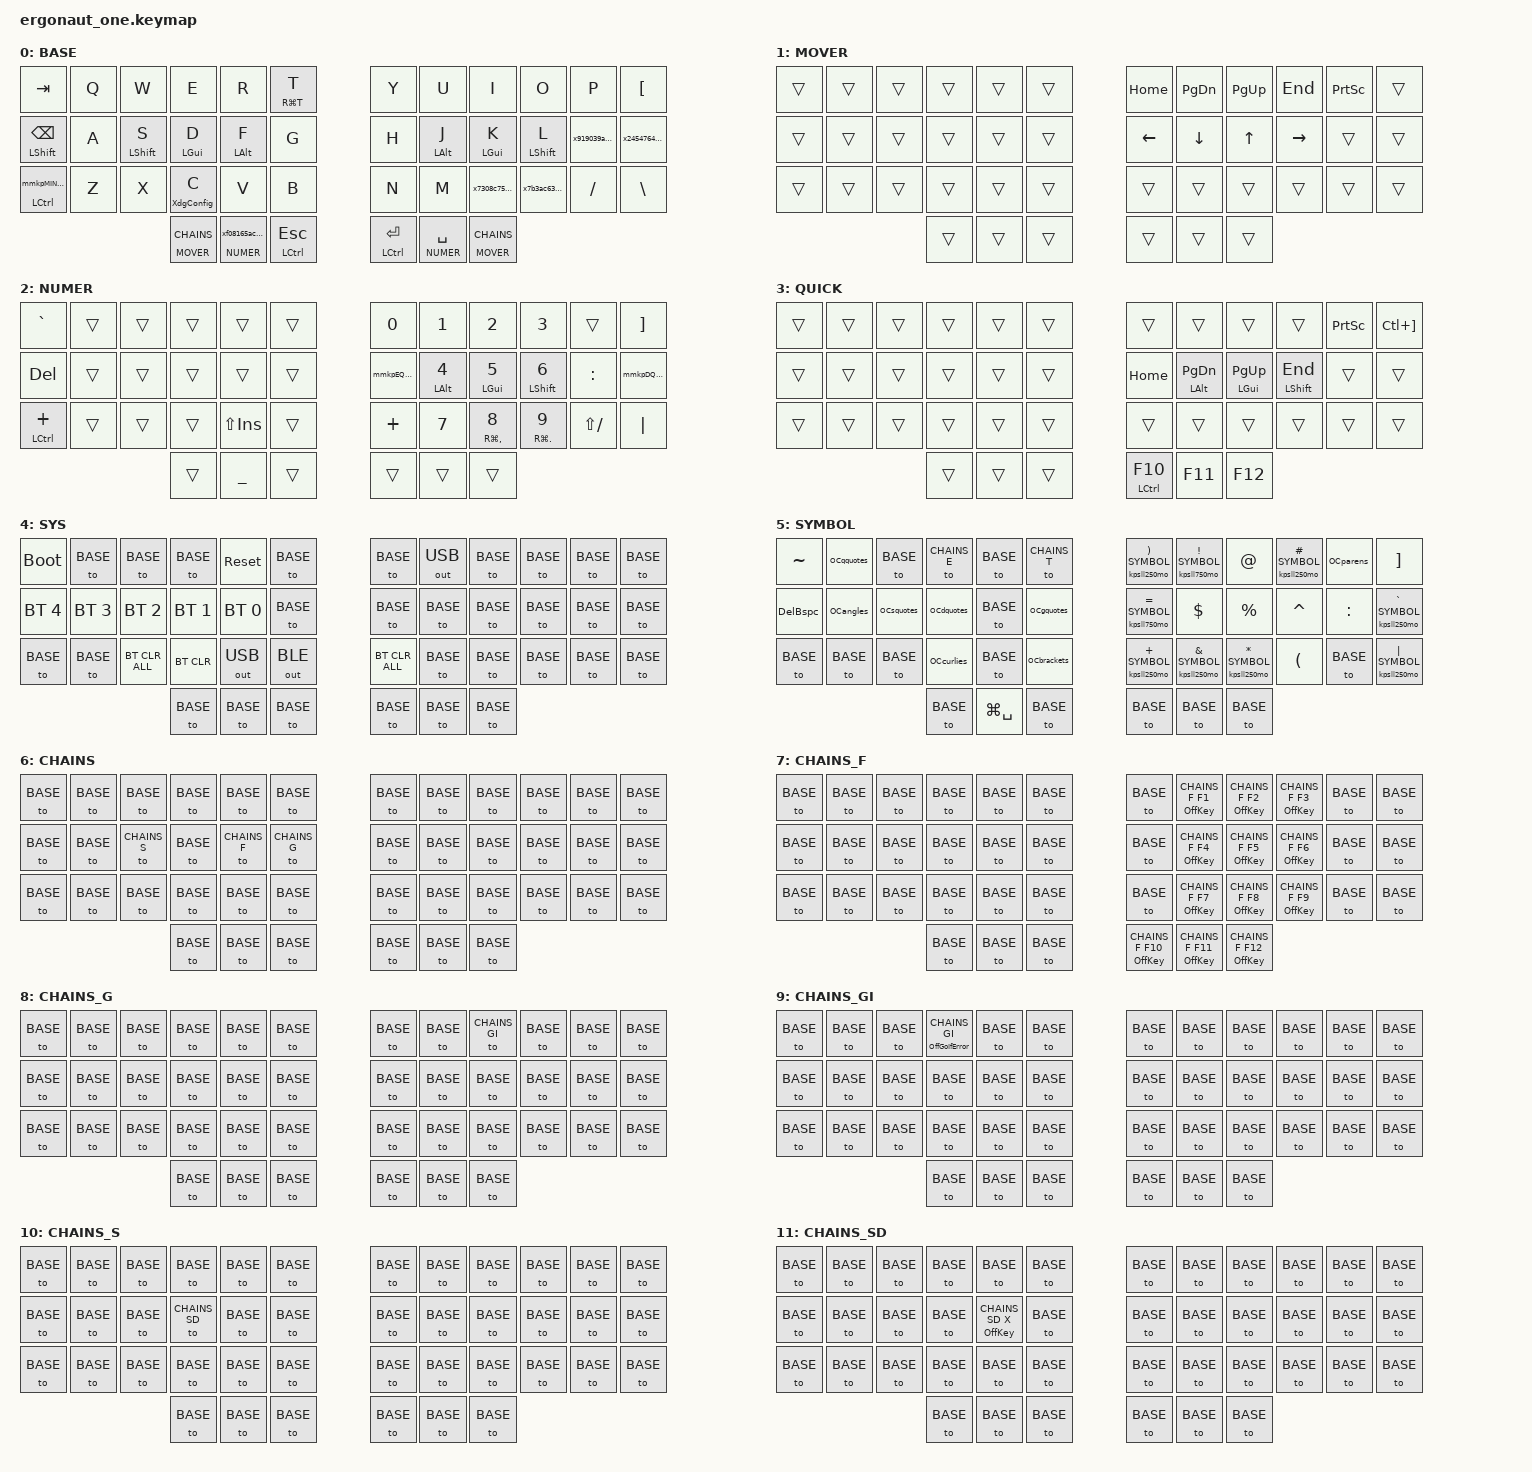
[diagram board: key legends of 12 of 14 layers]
#include <behaviors.dtsi>
#include <dt-bindings/zmk/bt.h>
#include <dt-bindings/zmk/keys.h>
#include <dt-bindings/zmk/outputs.h>
#include <dt-bindings/zmk/pointing.h>

#define BASE 0
#define MOVER 1
#define NUMER 2
#define QUICK 3
#define SYS 4
#define SYMBOL 5
#define CHAINS 6
#define CHAINS_F 7
#define CHAINS_G 8
#define CHAINS_GI 9
#define CHAINS_S 10
#define CHAINS_SD 11
#define CHAINS_E 12
#define CHAINS_T 13

&lt {
    quick-tap-ms = <200>;
    flavor = "balanced";
};

&mt {
    quick-tap-ms = <200>;
    flavor = "tap-preferred";
};

&caps_word {
    continue-list = <UNDER BSPC DEL LEFT RIGHT UP DOWN PG_UP PG_DN>;
};

/ {
    conditional_layers {
        compatible = "zmk,conditional-layers";
    };

    behaviors {
        OlHtOlKpkp: OlHtOlKpkp {
            compatible = "zmk,behavior-hold-tap";
            #binding-cells = <2>;
            bindings = <&OlKp &kp>;
            flavor = "tap-preferred";
            quick-tap-ms = <0>;
            tapping-term-ms = <300>;
        };

        htTapNoRepeatkp: htTapNoRepeatkp {
            compatible = "zmk,behavior-hold-tap";
            #binding-cells = <2>;
            bindings = <&TapNoRepeat &kp>;
            flavor = "tap-preferred";
            quick-tap-ms = <200>;
            tapping-term-ms = <200>;
        };

        htkpcaps_word: htkpcaps_word {
            compatible = "zmk,behavior-hold-tap";
            #binding-cells = <2>;
            bindings = <&kp &caps_word>;
            flavor = "tap-preferred";
            quick-tap-ms = <200>;
            tapping-term-ms = <200>;
        };

        htkpsklkp: htkpsklkp {
            compatible = "zmk,behavior-hold-tap";
            #binding-cells = <2>;
            bindings = <&kp &sklkp>;
            flavor = "tap-preferred";
            quick-tap-ms = <200>;
            tapping-term-ms = <200>;
        };

        mkpmmkpMINUSkpPLUS: mkpmmkpMINUSkpPLUS {
            compatible = "zmk,behavior-hold-tap";
            #binding-cells = <2>;
            bindings = <&kp &mmkpMINUSkpPLUS>;
            flavor = "tap-preferred";
            quick-tap-ms = <200>;
            tapping-term-ms = <200>;
        };

        mmkpDQTkpGRAVE: mmkpDQTkpGRAVE {
            compatible = "zmk,behavior-mod-morph";
            #binding-cells = <0>;
            bindings = <&kp DQT &kp GRAVE>;
            mods = <(MOD_LSFT|MOD_RSFT)>;
        };

        mmkpEQUALkpEQUAL: mmkpEQUALkpEQUAL {
            compatible = "zmk,behavior-mod-morph";
            #binding-cells = <0>;
            bindings = <&kp EQUAL &kp EQUAL>;
            mods = <(MOD_LSFT|MOD_RSFT)>;
        };

        mmkpMINUSkpPLUS: mmkpMINUSkpPLUS {
            compatible = "zmk,behavior-mod-morph";
            #binding-cells = <0>;
            bindings = <&kp MINUS &kp PLUS>;
            keep-mods = <(MOD_LCTL|MOD_RCTL)>;
            mods = <(MOD_LSFT|MOD_RSFT|MOD_LCTL|MOD_RCTL)>;
        };

        momoxf08165acddbe: momoxf08165acddbe {
            compatible = "zmk,behavior-hold-tap";
            #binding-cells = <2>;
            bindings = <&mo &xf08165acddbe>;
            flavor = "balanced";
            tapping-term-ms = <300>;
        };

        motomoto: motomoto {
            compatible = "zmk,behavior-hold-tap";
            #binding-cells = <2>;
            bindings = <&mo &to>;
            flavor = "balanced";
            tapping-term-ms = <300>;
        };

        off: off {
            compatible = "zmk,behavior-toggle-layer";
            #binding-cells = <1>;
            display-name = "Layer Off";
            toggle-mode = "off";
        };

        rmtkpkp: rmtkpkp {
            compatible = "zmk,behavior-hold-tap";
            #binding-cells = <2>;
            bindings = <&kp &kp>;
            flavor = "tap-preferred";
            hold-trigger-key-positions = <0 1 2 3 4 5 12 13 14 15 16 17 24 25 26 27 28 29 36 37 38 19 20 21 39 40 41>;
            hold-trigger-on-release;
            quick-tap-ms = <200>;
            tapping-term-ms = <250>;
        };

        sklkp: sklkp {
            compatible = "zmk,behavior-sticky-key";
            #binding-cells = <1>;
            bindings = <&kp>;
            ignore-modifiers;
            lazy;
            quick-release;
            release-after-ms = <9000>;
        };

        sll250mo: sll250mo {
            compatible = "zmk,behavior-sticky-key";
            #binding-cells = <1>;
            bindings = <&mo>;
            quick-release;
            release-after-ms = <250>;
        };

        sll500mo: sll500mo {
            compatible = "zmk,behavior-sticky-key";
            #binding-cells = <1>;
            bindings = <&mo>;
            quick-release;
            release-after-ms = <500>;
        };

        sll750mo: sll750mo {
            compatible = "zmk,behavior-sticky-key";
            #binding-cells = <1>;
            bindings = <&mo>;
            quick-release;
            release-after-ms = <750>;
        };

        x245476459fa2: x245476459fa2 {
            compatible = "zmk,behavior-mod-morph";
            #binding-cells = <0>;
            bindings = <&OlHtOlKpkp SQT SQT &OlHtOlKpkp LS(SQT) LS(SQT)>;
            mods = <(MOD_LSFT)>;
        };

        x7308c75c96cf: x7308c75c96cf {
            compatible = "zmk,behavior-mod-morph";
            #binding-cells = <0>;
            bindings = <&OlHtOlKpkp COMMA COMMA &OlHtOlKpkp LS(COMMA) LS(COMMA)>;
            mods = <(MOD_LSFT)>;
        };

        x7b3ac633c15b: x7b3ac633c15b {
            compatible = "zmk,behavior-mod-morph";
            #binding-cells = <0>;
            bindings = <&OlHtOlKpkp DOT DOT &OlHtOlKpkp LS(DOT) LS(DOT)>;
            mods = <(MOD_LSFT)>;
        };

        x919039aa9eaf: x919039aa9eaf {
            compatible = "zmk,behavior-mod-morph";
            #binding-cells = <0>;
            bindings = <&OlHtOlKpkp SEMI SEMI &OlHtOlKpkp LS(SEMI) LS(SEMI)>;
            mods = <(MOD_LSFT)>;
        };

        xf08165acddbe: xf08165acddbe {
            compatible = "zmk,behavior-mod-morph";
            #binding-cells = <0>;
            bindings = <&sll500mo SYMBOL &kp UNDER>;
            mods = <(MOD_LSFT|MOD_RSFT)>;
        };

        xkpXdgConfigkp: xkpXdgConfigkp {
            compatible = "zmk,behavior-hold-tap";
            #binding-cells = <2>;
            bindings = <&XdgConfig &kp>;
            flavor = "tap-preferred";
            quick-tap-ms = <200>;
            tapping-term-ms = <350>;
        };

    };

    macros {
        DelBspc: DelBspc {
            compatible = "zmk,behavior-macro";
            #binding-cells = <0>;
            bindings = <&kp DEL &kp BSPC>;
        };

        EOCangles: EOCangles {
            compatible = "zmk,behavior-macro";
            #binding-cells = <0>;
            bindings = <&kp BACKSLASH &kp LT &kp BACKSLASH &kp GT &kp LEFT &kp LEFT>;
        };

        EOCbrackets: EOCbrackets {
            compatible = "zmk,behavior-macro";
            #binding-cells = <0>;
            bindings = <&kp BACKSLASH &kp LBKT &kp BACKSLASH &kp RBKT &kp LEFT &kp LEFT>;
        };

        EOCcurlies: EOCcurlies {
            compatible = "zmk,behavior-macro";
            #binding-cells = <0>;
            bindings = <&kp BACKSLASH &kp LBRC &kp BACKSLASH &kp RBRC &kp LEFT &kp LEFT>;
        };

        EOCdquotes: EOCdquotes {
            compatible = "zmk,behavior-macro";
            #binding-cells = <0>;
            bindings = <&kp BACKSLASH &kp DQT &kp BACKSLASH &kp DQT &kp LEFT &kp LEFT>;
        };

        EOCgquotes: EOCgquotes {
            compatible = "zmk,behavior-macro";
            #binding-cells = <0>;
            bindings = <&kp BACKSLASH &kp GRAVE &kp BACKSLASH &kp GRAVE &kp LEFT &kp LEFT>;
        };

        EOCparens: EOCparens {
            compatible = "zmk,behavior-macro";
            #binding-cells = <0>;
            bindings = <&kp BACKSLASH &kp LPAR &kp BACKSLASH &kp RPAR &kp LEFT &kp LEFT>;
        };

        EOCsquotes: EOCsquotes {
            compatible = "zmk,behavior-macro";
            #binding-cells = <0>;
            bindings = <&kp BACKSLASH &kp SQT &kp BACKSLASH &kp SQT &kp LEFT &kp LEFT>;
        };

        GoIfError: GoIfError {
            compatible = "zmk,behavior-macro";
            #binding-cells = <0>;
            bindings = <&kp G &kp O &kp SPACE &kp I &kp F &kp E &kp LEFT &kp N &kp LEFT &kp I &kp LEFT &kp F &kp LEFT>;
        };

        OCangles: OCangles {
            compatible = "zmk,behavior-macro";
            #binding-cells = <0>;
            bindings = <&kp LT &kp GT &kp LEFT>;
        };

        OCbrackets: OCbrackets {
            compatible = "zmk,behavior-macro";
            #binding-cells = <0>;
            bindings = <&kp LBKT &kp RBKT &kp LEFT>;
        };

        OCcurlies: OCcurlies {
            compatible = "zmk,behavior-macro";
            #binding-cells = <0>;
            bindings = <&kp LBRC &kp RBRC &kp LEFT>;
        };

        OCdquotes: OCdquotes {
            compatible = "zmk,behavior-macro";
            #binding-cells = <0>;
            bindings = <&kp DQT &kp DQT &kp LEFT>;
        };

        OCgquotes: OCgquotes {
            compatible = "zmk,behavior-macro";
            #binding-cells = <0>;
            bindings = <&kp GRAVE &kp GRAVE &kp LEFT>;
        };

        OCparens: OCparens {
            compatible = "zmk,behavior-macro";
            #binding-cells = <0>;
            bindings = <&kp LPAR &kp RPAR &kp LEFT>;
        };

        OCqquotes: OCqquotes {
            compatible = "zmk,behavior-macro";
            #binding-cells = <0>;
            bindings = <&kp GRAVE &kp GRAVE &kp LEFT>;
        };

        OCsquotes: OCsquotes {
            compatible = "zmk,behavior-macro";
            #binding-cells = <0>;
            bindings = <&kp SQT &kp SQT &kp LEFT>;
        };

        OffEOCangles: OffEOCangles {
            compatible = "zmk,behavior-macro-one-param";
            #binding-cells = <1>;
            bindings = <&macro_press &EOCangles &macro_pause_for_release &macro_release &EOCangles &macro_tap &macro_param_1to1 &off MACRO_PLACEHOLDER>;
        };

        OffEOCbrackets: OffEOCbrackets {
            compatible = "zmk,behavior-macro-one-param";
            #binding-cells = <1>;
            bindings = <&macro_press &EOCbrackets &macro_pause_for_release &macro_release &EOCbrackets &macro_tap &macro_param_1to1 &off MACRO_PLACEHOLDER>;
        };

        OffEOCcurlies: OffEOCcurlies {
            compatible = "zmk,behavior-macro-one-param";
            #binding-cells = <1>;
            bindings = <&macro_press &EOCcurlies &macro_pause_for_release &macro_release &EOCcurlies &macro_tap &macro_param_1to1 &off MACRO_PLACEHOLDER>;
        };

        OffEOCdquotes: OffEOCdquotes {
            compatible = "zmk,behavior-macro-one-param";
            #binding-cells = <1>;
            bindings = <&macro_press &EOCdquotes &macro_pause_for_release &macro_release &EOCdquotes &macro_tap &macro_param_1to1 &off MACRO_PLACEHOLDER>;
        };

        OffEOCgquotes: OffEOCgquotes {
            compatible = "zmk,behavior-macro-one-param";
            #binding-cells = <1>;
            bindings = <&macro_press &EOCgquotes &macro_pause_for_release &macro_release &EOCgquotes &macro_tap &macro_param_1to1 &off MACRO_PLACEHOLDER>;
        };

        OffEOCparens: OffEOCparens {
            compatible = "zmk,behavior-macro-one-param";
            #binding-cells = <1>;
            bindings = <&macro_press &EOCparens &macro_pause_for_release &macro_release &EOCparens &macro_tap &macro_param_1to1 &off MACRO_PLACEHOLDER>;
        };

        OffEOCsquotes: OffEOCsquotes {
            compatible = "zmk,behavior-macro-one-param";
            #binding-cells = <1>;
            bindings = <&macro_press &EOCsquotes &macro_pause_for_release &macro_release &EOCsquotes &macro_tap &macro_param_1to1 &off MACRO_PLACEHOLDER>;
        };

        OffGoIfError: OffGoIfError {
            compatible = "zmk,behavior-macro-one-param";
            #binding-cells = <1>;
            bindings = <&macro_press &GoIfError &macro_pause_for_release &macro_release &GoIfError &macro_tap &macro_param_1to1 &off MACRO_PLACEHOLDER>;
        };

        OffKey: OffKey {
            compatible = "zmk,behavior-macro-two-param";
            #binding-cells = <2>;
            bindings = <&macro_press &macro_param_2to1 &kp MACRO_PLACEHOLDER &macro_pause_for_release &macro_release &macro_param_2to1 &kp MACRO_PLACEHOLDER &macro_tap &macro_param_1to1 &off MACRO_PLACEHOLDER>;
        };

        OffTripleDQuote: OffTripleDQuote {
            compatible = "zmk,behavior-macro-one-param";
            #binding-cells = <1>;
            bindings = <&macro_press &TripleDQuote &macro_pause_for_release &macro_release &TripleDQuote &macro_tap &macro_param_1to1 &off MACRO_PLACEHOLDER>;
        };

        OffTripleSQuote: OffTripleSQuote {
            compatible = "zmk,behavior-macro-one-param";
            #binding-cells = <1>;
            bindings = <&macro_press &TripleSQuote &macro_pause_for_release &macro_release &TripleSQuote &macro_tap &macro_param_1to1 &off MACRO_PLACEHOLDER>;
        };

        OffTriplgGQuote: OffTriplgGQuote {
            compatible = "zmk,behavior-macro-one-param";
            #binding-cells = <1>;
            bindings = <&macro_press &TriplgGQuote &macro_pause_for_release &macro_release &TriplgGQuote &macro_tap &macro_param_1to1 &off MACRO_PLACEHOLDER>;
        };

        OlKp: OlKp {
            compatible = "zmk,behavior-macro-one-param";
            #binding-cells = <1>;
            wait-ms = <100>;
            bindings = <&kp LG(SPACE) &macro_param_1to1 &kp MACRO_PLACEHOLDER &kp LG(SPACE)>;
        };

        TapNoRepeat: TapNoRepeat {
            compatible = "zmk,behavior-macro-one-param";
            #binding-cells = <1>;
            bindings = <&macro_param_1to1 &kp MACRO_PLACEHOLDER &macro_pause_for_release>;
        };

        TripleDQuote: TripleDQuote {
            compatible = "zmk,behavior-macro";
            #binding-cells = <0>;
            bindings = <&kp DQT &kp DQT &kp DQT>;
        };

        TripleSQuote: TripleSQuote {
            compatible = "zmk,behavior-macro";
            #binding-cells = <0>;
            bindings = <&kp SQT &kp SQT &kp SQT>;
        };

        TriplgGQuote: TriplgGQuote {
            compatible = "zmk,behavior-macro";
            #binding-cells = <0>;
            bindings = <&kp GRAVE &kp GRAVE &kp GRAVE &kp GRAVE &kp LEFT &kp GRAVE &kp LEFT &kp GRAVE &kp LEFT>;
        };

        XdgConfig: XdgConfig {
            compatible = "zmk,behavior-macro";
            #binding-cells = <0>;
            bindings = <&kp DQT &kp DOLLAR &kp LS(H) &kp LS(O) &kp LS(M) &kp LS(E) &kp SLASH &kp DOT &kp C &kp O &kp N &kp F &kp I &kp G &kp DQT &kp SLASH>;
        };

        kpsll250mo: kpsll250mo {
            compatible = "zmk,behavior-macro-two-param";
            #binding-cells = <2>;
            bindings = <&macro_param_1to1 &kp MACRO_PLACEHOLDER &macro_param_2to1 &sll250mo MACRO_PLACEHOLDER>;
        };

        kpsll750mo: kpsll750mo {
            compatible = "zmk,behavior-macro-two-param";
            #binding-cells = <2>;
            bindings = <&macro_param_1to1 &kp MACRO_PLACEHOLDER &macro_param_2to1 &sll750mo MACRO_PLACEHOLDER>;
        };

    };

    combos {
        compatible = "zmk,combos";
        System {
            bindings = <&to SYS>;
            key-positions = <4 5>;
            timeout-ms = <100>;
            require-prior-idle-ms = <500>;
        };

        LeftEnter {
            bindings = <&kp RETURN>;
            key-positions = <37 38>;
        };

        LeftSpace {
            bindings = <&kp SPACE>;
            key-positions = <36 37>;
        };

        BottomLeftCtrlShift {
            bindings = <&kp LC(LSHIFT)>;
            key-positions = <12 24>;
        };

        LeftStickyCombo_LALT_LGUI_LSHIFT_LCTRL {
            bindings = <&htkpsklkp LC(LS(LG(LALT))) LC(LS(LG(LALT)))>;
            key-positions = <16 15 14 38>;
        };

        LeftStickyCombo_LALT_LGUI_LSHIFT {
            bindings = <&htkpsklkp LS(LG(LALT)) LS(LG(LALT))>;
            key-positions = <16 15 14>;
        };

        LeftStickyCombo_LALT_LGUI {
            bindings = <&htkpsklkp LG(LALT) LG(LALT)>;
            key-positions = <16 15>;
        };

        LeftStickyCombo_LALT_LSHIFT {
            bindings = <&htkpsklkp LS(LALT) LS(LALT)>;
            key-positions = <16 14>;
        };

        LeftStickyCombo_LGUI_LSHIFT {
            bindings = <&htkpsklkp LS(LGUI) LS(LGUI)>;
            key-positions = <15 14>;
        };

        LeftStickyCombo_LALT_LGUI_LCTRL {
            bindings = <&htkpsklkp LC(LG(LALT)) LC(LG(LALT))>;
            key-positions = <16 15 38>;
        };

        LeftStickyCombo_LALT_LCTRL {
            bindings = <&htkpsklkp LC(LALT) LC(LALT)>;
            key-positions = <16 38>;
        };

        LeftStickyCombo_LGUI_LCTRL {
            bindings = <&htkpsklkp LC(LGUI) LC(LGUI)>;
            key-positions = <15 38>;
        };

        LeftStickyCombo_LALT_LSHIFT_LCTRL {
            bindings = <&htkpsklkp LC(LS(LALT)) LC(LS(LALT))>;
            key-positions = <16 14 38>;
        };

        LeftStickyCombo_LSHIFT_LCTRL {
            bindings = <&htkpsklkp LC(LSHIFT) LC(LSHIFT)>;
            key-positions = <14 38>;
        };

        LeftStickyCombo_LGUI_LSHIFT_LCTRL {
            bindings = <&htkpsklkp LC(LS(LGUI)) LC(LS(LGUI))>;
            key-positions = <15 14 38>;
        };

        RightAltWinShift {
            bindings = <&kp LA(LG(LSHIFT))>;
            key-positions = <19 20 21>;
        };

        RightWinShift_Caps {
            bindings = <&htkpcaps_word LG(LSHIFT) 0>;
            key-positions = <20 21>;
        };

        MiddleMouse {
            bindings = <&mkp MCLK>;
            key-positions = <27 28>;
            timeout-ms = <100>;
            require-prior-idle-ms = <200>;
        };

    };

    keymap {
        compatible = "zmk,keymap";
        BASE {
            bindings = <
&kp TAB                      &kp Q  &kp W         &kp E                   &kp R                       &htTapNoRepeatkp RG(T) T  &kp Y             &kp U            &kp I                   &kp O              &kp P           &kp LBKT
&mt LSHIFT BACKSPACE         &kp A  &mt LSHIFT S  &mt LGUI D              &mt LALT F                  &kp G                     &kp H             &mt LALT J       &mt LGUI K              &rmtkpkp LSHIFT L  &x919039aa9eaf  &x245476459fa2
&mkpmmkpMINUSkpPLUS LCTRL 0  &kp Z  &kp X         &xkpXdgConfigkp 0 C     &kp V                       &kp B                     &kp N             &kp M            &x7308c75c96cf          &x7b3ac633c15b     &kp SLASH       &kp BACKSLASH
                                                  &motomoto MOVER CHAINS  &momoxf08165acddbe NUMER 0  &mt LCTRL ESCAPE          &mt LCTRL RETURN  &lt NUMER SPACE  &motomoto MOVER CHAINS
            >;
        };

        MOVER {
            bindings = <
&trans  &trans  &trans  &trans  &trans  &trans  &kp HOME  &kp PG_DN  &kp PG_UP  &kp END    &kp PSCRN  &trans
&trans  &trans  &trans  &trans  &trans  &trans  &kp LEFT  &kp DOWN   &kp UP     &kp RIGHT  &trans     &trans
&trans  &trans  &trans  &trans  &trans  &trans  &trans    &trans     &trans     &trans     &trans     &trans
                        &trans  &trans  &trans  &trans    &trans     &trans
            >;
        };

        NUMER {
            bindings = <
&kp GRAVE       &trans  &trans  &trans  &trans          &trans  &kp N0             &kp N1       &kp N2                         &kp N3                       &trans         &kp RBKT
&kp DELETE      &trans  &trans  &trans  &trans          &trans  &mmkpEQUALkpEQUAL  &mt LALT N4  &mt LGUI N5                    &mt LSHIFT N6                &kp COLON      &mmkpDQTkpGRAVE
&mt LCTRL PLUS  &trans  &trans  &trans  &kp LS(INSERT)  &trans  &kp PLUS           &kp N7       &htTapNoRepeatkp RG(COMMA) N8  &htTapNoRepeatkp RG(DOT) N9  &kp LS(SLASH)  &kp PIPE
                                &trans  &kp UNDERSCORE  &trans  &trans             &trans       &trans
            >;
        };

        QUICK {
            bindings = <
&trans  &trans  &trans  &trans  &trans  &trans  &trans         &trans          &trans          &trans          &kp PSCRN  &kp LC(RBKT)
&trans  &trans  &trans  &trans  &trans  &trans  &kp HOME       &mt LALT PG_DN  &mt LGUI PG_UP  &mt LSHIFT END  &trans     &trans
&trans  &trans  &trans  &trans  &trans  &trans  &trans         &trans          &trans          &trans          &trans     &trans
                        &trans  &trans  &trans  &mt LCTRL F10  &kp F11         &kp F12
            >;
        };

        SYS {
            bindings = <
&bootloader   &to BASE      &to BASE        &to BASE      &sys_reset    &to BASE      &to BASE        &out OUT_USB  &to BASE  &to BASE  &to BASE  &to BASE
&bt BT_SEL 4  &bt BT_SEL 3  &bt BT_SEL 2    &bt BT_SEL 1  &bt BT_SEL 0  &to BASE      &to BASE        &to BASE      &to BASE  &to BASE  &to BASE  &to BASE
&to BASE      &to BASE      &bt BT_CLR_ALL  &bt BT_CLR    &out OUT_USB  &out OUT_BLE  &bt BT_CLR_ALL  &to BASE      &to BASE  &to BASE  &to BASE  &to BASE
                                            &to BASE      &to BASE      &to BASE      &to BASE        &to BASE      &to BASE
            >;
        };

        SYMBOL {
            bindings = <
&kp TILDE  &OCqquotes  &to BASE    &to CHAINS_E  &to BASE       &to CHAINS_T  &kpsll250mo RPAR SYMBOL   &kpsll750mo EXCL SYMBOL  &kp AT                   &kpsll250mo HASH SYMBOL  &OCparens  &kp RBKT
&DelBspc   &OCangles   &OCsquotes  &OCdquotes    &to BASE       &OCgquotes    &kpsll750mo EQUAL SYMBOL  &kp DLLR                 &kp PRCNT                &kp CARET                &kp COLON  &kpsll250mo GRAVE SYMBOL
&to BASE   &to BASE    &to BASE    &OCcurlies    &to BASE       &OCbrackets   &kpsll250mo PLUS SYMBOL   &kpsll250mo AMPS SYMBOL  &kpsll250mo STAR SYMBOL  &kp LPAR                 &to BASE   &kpsll250mo PIPE SYMBOL
                                   &to BASE      &kp LG(SPACE)  &to BASE      &to BASE                  &to BASE                 &to BASE
            >;
        };

        CHAINS {
            bindings = <
&to BASE  &to BASE  &to BASE      &to BASE  &to BASE      &to BASE      &to BASE  &to BASE  &to BASE  &to BASE  &to BASE  &to BASE
&to BASE  &to BASE  &to CHAINS_S  &to BASE  &to CHAINS_F  &to CHAINS_G  &to BASE  &to BASE  &to BASE  &to BASE  &to BASE  &to BASE
&to BASE  &to BASE  &to BASE      &to BASE  &to BASE      &to BASE      &to BASE  &to BASE  &to BASE  &to BASE  &to BASE  &to BASE
                                  &to BASE  &to BASE      &to BASE      &to BASE  &to BASE  &to BASE
            >;
        };

        CHAINS_F {
            bindings = <
&to BASE  &to BASE  &to BASE  &to BASE  &to BASE  &to BASE  &to BASE              &OffKey CHAINS_F F1   &OffKey CHAINS_F F2   &OffKey CHAINS_F F3  &to BASE  &to BASE
&to BASE  &to BASE  &to BASE  &to BASE  &to BASE  &to BASE  &to BASE              &OffKey CHAINS_F F4   &OffKey CHAINS_F F5   &OffKey CHAINS_F F6  &to BASE  &to BASE
&to BASE  &to BASE  &to BASE  &to BASE  &to BASE  &to BASE  &to BASE              &OffKey CHAINS_F F7   &OffKey CHAINS_F F8   &OffKey CHAINS_F F9  &to BASE  &to BASE
                              &to BASE  &to BASE  &to BASE  &OffKey CHAINS_F F10  &OffKey CHAINS_F F11  &OffKey CHAINS_F F12
            >;
        };

        CHAINS_G {
            bindings = <
&to BASE  &to BASE  &to BASE  &to BASE  &to BASE  &to BASE  &to BASE  &to BASE  &to CHAINS_GI  &to BASE  &to BASE  &to BASE
&to BASE  &to BASE  &to BASE  &to BASE  &to BASE  &to BASE  &to BASE  &to BASE  &to BASE       &to BASE  &to BASE  &to BASE
&to BASE  &to BASE  &to BASE  &to BASE  &to BASE  &to BASE  &to BASE  &to BASE  &to BASE       &to BASE  &to BASE  &to BASE
                              &to BASE  &to BASE  &to BASE  &to BASE  &to BASE  &to BASE
            >;
        };

        CHAINS_GI {
            bindings = <
&to BASE  &to BASE  &to BASE  &OffGoIfError CHAINS_GI  &to BASE  &to BASE  &to BASE  &to BASE  &to BASE  &to BASE  &to BASE  &to BASE
&to BASE  &to BASE  &to BASE  &to BASE                 &to BASE  &to BASE  &to BASE  &to BASE  &to BASE  &to BASE  &to BASE  &to BASE
&to BASE  &to BASE  &to BASE  &to BASE                 &to BASE  &to BASE  &to BASE  &to BASE  &to BASE  &to BASE  &to BASE  &to BASE
                              &to BASE                 &to BASE  &to BASE  &to BASE  &to BASE  &to BASE
            >;
        };

        CHAINS_S {
            bindings = <
&to BASE  &to BASE  &to BASE  &to BASE       &to BASE  &to BASE  &to BASE  &to BASE  &to BASE  &to BASE  &to BASE  &to BASE
&to BASE  &to BASE  &to BASE  &to CHAINS_SD  &to BASE  &to BASE  &to BASE  &to BASE  &to BASE  &to BASE  &to BASE  &to BASE
&to BASE  &to BASE  &to BASE  &to BASE       &to BASE  &to BASE  &to BASE  &to BASE  &to BASE  &to BASE  &to BASE  &to BASE
                              &to BASE       &to BASE  &to BASE  &to BASE  &to BASE  &to BASE
            >;
        };

        CHAINS_SD {
            bindings = <
&to BASE  &to BASE  &to BASE  &to BASE  &to BASE             &to BASE  &to BASE  &to BASE  &to BASE  &to BASE  &to BASE  &to BASE
&to BASE  &to BASE  &to BASE  &to BASE  &OffKey CHAINS_SD X  &to BASE  &to BASE  &to BASE  &to BASE  &to BASE  &to BASE  &to BASE
&to BASE  &to BASE  &to BASE  &to BASE  &to BASE             &to BASE  &to BASE  &to BASE  &to BASE  &to BASE  &to BASE  &to BASE
                              &to BASE  &to BASE             &to BASE  &to BASE  &to BASE  &to BASE
            >;
        };

        CHAINS_E {
            bindings = <
&to BASE  &to BASE                &to BASE                 &to BASE                 &to BASE  &to BASE                  &to BASE  &to BASE  &to BASE  &to BASE  &OffEOCparens CHAINS_E  &to BASE
&to BASE  &OffEOCangles CHAINS_E  &OffEOCsquotes CHAINS_E  &OffEOCdquotes CHAINS_E  &to BASE  &OffEOCgquotes CHAINS_E   &to BASE  &to BASE  &to BASE  &to BASE  &to BASE                &to BASE
&to BASE  &to BASE                &to BASE                 &OffEOCcurlies CHAINS_E  &to BASE  &OffEOCbrackets CHAINS_E  &to BASE  &to BASE  &to BASE  &to BASE  &to BASE                &to BASE
                                                           &to BASE                 &to BASE  &to BASE                  &to BASE  &to BASE  &to BASE
            >;
        };

        CHAINS_T {
            bindings = <
&to BASE  &to BASE  &to BASE                   &to BASE                   &to BASE  &to BASE                   &to BASE  &to BASE  &to BASE  &to BASE  &to BASE  &to BASE
&to BASE  &to BASE  &OffTripleSQuote CHAINS_T  &OffTripleDQuote CHAINS_T  &to BASE  &OffTriplgGQuote CHAINS_T  &to BASE  &to BASE  &to BASE  &to BASE  &to BASE  &to BASE
&to BASE  &to BASE  &to BASE                   &to BASE                   &to BASE  &to BASE                   &to BASE  &to BASE  &to BASE  &to BASE  &to BASE  &to BASE
                                               &to BASE                   &to BASE  &to BASE                   &to BASE  &to BASE  &to BASE
            >;
        };

    };
};
